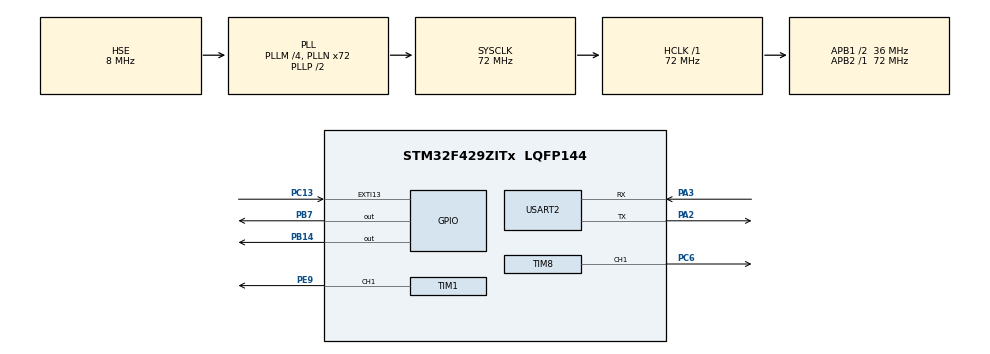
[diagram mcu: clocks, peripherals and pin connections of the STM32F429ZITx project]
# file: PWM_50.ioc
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Mcu.Family=STM32F4
Mcu.Name=STM32F429ZITx
Mcu.Package=LQFP144
NVIC.PriorityGroup=NVIC_PRIORITYGROUP_4
PA13.Mode=Serial_Wire
PA13.Signal=SYS_JTMS-SWDIO
PA14.Mode=Serial_Wire
PA14.Signal=SYS_JTCK-SWCLK
PA2.Mode=Asynchronous
PA2.Signal=USART2_TX
PA3.Mode=Asynchronous
PA3.Signal=USART2_RX
PB14.Signal=GPIO_Output
PB7.Signal=GPIO_Output
PC13.Signal=GPXTI13
PC6.Signal=S_TIM8_CH1
PE9.Signal=S_TIM1_CH1
PH0/OSC_IN.Mode=HSE-External-Oscillator
PH0/OSC_IN.Signal=RCC_OSC_IN
PH1/OSC_OUT.Mode=HSE-External-Oscillator
PH1/OSC_OUT.Signal=RCC_OSC_OUT
ProjectManager.HeapSize=0x200
ProjectManager.StackSize=0x400
ProjectManager.TargetToolchain=STM32CubeIDE
RCC.48MHZClocksFreq_Value=36000000
RCC.AHBFreq_Value=72000000
RCC.APB1CLKDivider=RCC_HCLK_DIV2
RCC.APB1Freq_Value=36000000
RCC.APB1TimFreq_Value=72000000
RCC.APB2Freq_Value=72000000
RCC.APB2TimFreq_Value=72000000
RCC.CortexFreq_Value=72000000
RCC.HCLKFreq_Value=72000000
RCC.HSE_VALUE=8000000
RCC.HSI_VALUE=16000000
RCC.LSE_VALUE=32768
RCC.PLLM=4
RCC.PLLN=72
RCC.PLLSourceVirtual=RCC_PLLSOURCE_HSE
RCC.SYSCLKFreq_VALUE=72000000
RCC.SYSCLKSource=RCC_SYSCLKSOURCE_PLLCLK
RCC.VCOOutputFreq_Value=144000000
SH.S_TIM1_CH1.0=TIM1_CH1,PWM Generation1 CH1
SH.S_TIM8_CH1.0=TIM8_CH1,PWM Generation1 CH1
TIM1.Channel-Output\ Compare2\ No\ Output=TIM_CHANNEL_2
TIM1.Channel-PWM\ Generation1\ CH1=TIM_CHANNEL_1
TIM1.OCMode_2=TIM_OCMODE_ACTIVE
TIM1.Period=199
TIM1.Prescaler=71
TIM1.Pulse-Output\ Compare2\ No\ Output=100
TIM1.Pulse-PWM\ Generation1\ CH1=100
TIM1.TIM_MasterOutputTrigger=TIM_TRGO_OC2REF
TIM8.Channel-PWM\ Generation1\ CH1=TIM_CHANNEL_1
TIM8.Period=199
TIM8.Prescaler=71
TIM8.Pulse-PWM\ Generation1\ CH1=100
TIM8.TIM_MasterOutputTrigger=TIM_TRGO_RESET
USART2.VirtualMode=VM_ASYNC
VP_TIM1_VS_ClockSourceINT.Mode=Internal
VP_TIM1_VS_no_output2.Mode=Output Compare2 No Output
VP_TIM8_VS_ClockSourceITR.Mode=TriggerSource_ITR0
VP_TIM8_VS_ControllerModeTrigger.Mode=Trigger Mode
board=custom

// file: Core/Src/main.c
/* USER CODE BEGIN Header */
/**
  ******************************************************************************
  * @file           : main.c
  * @brief          : Main program body
  ******************************************************************************
  * @attention
  *
  * Copyright (c) 2023 STMicroelectronics.
  * All rights reserved.
  *
  * This software is licensed under terms that can be found in the LICENSE file
  * in the root directory of this software component.
  * If no LICENSE file comes with this software, it is provided AS-IS.
  *
  ******************************************************************************
  */
/* USER CODE END Header */
#include "main.h"

/* USER CODE BEGIN Includes */
#include<stdio.h>
/* USER CODE END Includes */

TIM_HandleTypeDef htim1;
TIM_HandleTypeDef htim8;

UART_HandleTypeDef huart2;

void SystemClock_Config(void);
static void MX_GPIO_Init(void);
static void MX_TIM1_Init(void);
static void MX_USART2_UART_Init(void);
static void MX_TIM8_Init(void);

/* USER CODE BEGIN 0 */
int _write(int file, char *ptr, int len)
{
	HAL_UART_Transmit(&huart2, (uint8_t *)ptr, len, HAL_MAX_DELAY);
	return len;
}
/* USER CODE END 0 */

int main(void)
{

  /* MCU Configuration--------------------------------------------------------*/

  /* Reset of all peripherals, Initializes the Flash interface and the Systick. */
  HAL_Init();

  /* Configure the system clock */
  SystemClock_Config();

  /* Initialize all configured peripherals */
  MX_GPIO_Init();
  MX_TIM1_Init();
  MX_USART2_UART_Init();
  MX_TIM8_Init();
  /* USER CODE BEGIN 2 */

  HAL_TIM_PWM_Start(&htim1, TIM_CHANNEL_1);
  HAL_TIM_OC_Start(&htim1, TIM_CHANNEL_2);

  HAL_TIM_PWM_Start(&htim8, TIM_CHANNEL_1);

  /* USER CODE END 2 */

  /* Infinite loop */
  while (1)
  {

  }
}

void SystemClock_Config(void)
{
  RCC_OscInitTypeDef RCC_OscInitStruct = {0};
  RCC_ClkInitTypeDef RCC_ClkInitStruct = {0};

  /** Configure the main internal regulator output voltage
  */
  __HAL_RCC_PWR_CLK_ENABLE();
  __HAL_PWR_VOLTAGESCALING_CONFIG(PWR_REGULATOR_VOLTAGE_SCALE3);

  /** Initializes the RCC Oscillators according to the specified parameters
  * in the RCC_OscInitTypeDef structure.
  */
  RCC_OscInitStruct.OscillatorType = RCC_OSCILLATORTYPE_HSE;
  RCC_OscInitStruct.HSEState = RCC_HSE_ON;
  RCC_OscInitStruct.PLL.PLLState = RCC_PLL_ON;
  RCC_OscInitStruct.PLL.PLLSource = RCC_PLLSOURCE_HSE;
  RCC_OscInitStruct.PLL.PLLM = 4;
  RCC_OscInitStruct.PLL.PLLN = 72;
  RCC_OscInitStruct.PLL.PLLP = RCC_PLLP_DIV2;
  RCC_OscInitStruct.PLL.PLLQ = 4;
  if (HAL_RCC_OscConfig(&RCC_OscInitStruct) != HAL_OK)
  {
    Error_Handler();
  }

  /** Initializes the CPU, AHB and APB buses clocks
  */
  RCC_ClkInitStruct.ClockType = RCC_CLOCKTYPE_HCLK|RCC_CLOCKTYPE_SYSCLK
                              |RCC_CLOCKTYPE_PCLK1|RCC_CLOCKTYPE_PCLK2;
  RCC_ClkInitStruct.SYSCLKSource = RCC_SYSCLKSOURCE_PLLCLK;
  RCC_ClkInitStruct.AHBCLKDivider = RCC_SYSCLK_DIV1;
  RCC_ClkInitStruct.APB1CLKDivider = RCC_HCLK_DIV2;
  RCC_ClkInitStruct.APB2CLKDivider = RCC_HCLK_DIV1;

  if (HAL_RCC_ClockConfig(&RCC_ClkInitStruct, FLASH_LATENCY_2) != HAL_OK)
  {
    Error_Handler();
  }
}

static void MX_TIM1_Init(void)
{

  TIM_ClockConfigTypeDef sClockSourceConfig = {0};
  TIM_MasterConfigTypeDef sMasterConfig = {0};
  TIM_OC_InitTypeDef sConfigOC = {0};
  TIM_BreakDeadTimeConfigTypeDef sBreakDeadTimeConfig = {0};

  htim1.Instance = TIM1;
  htim1.Init.Prescaler = 71;
  htim1.Init.CounterMode = TIM_COUNTERMODE_UP;
  htim1.Init.Period = 199;
  htim1.Init.ClockDivision = TIM_CLOCKDIVISION_DIV1;
  htim1.Init.RepetitionCounter = 0;
  htim1.Init.AutoReloadPreload = TIM_AUTORELOAD_PRELOAD_DISABLE;
  if (HAL_TIM_Base_Init(&htim1) != HAL_OK)
  {
    Error_Handler();
  }
  sClockSourceConfig.ClockSource = TIM_CLOCKSOURCE_INTERNAL;
  if (HAL_TIM_ConfigClockSource(&htim1, &sClockSourceConfig) != HAL_OK)
  {
    Error_Handler();
  }
  if (HAL_TIM_PWM_Init(&htim1) != HAL_OK)
  {
    Error_Handler();
  }
  if (HAL_TIM_OC_Init(&htim1) != HAL_OK)
  {
    Error_Handler();
  }
  sMasterConfig.MasterOutputTrigger = TIM_TRGO_OC2REF;
  sMasterConfig.MasterSlaveMode = TIM_MASTERSLAVEMODE_DISABLE;
  if (HAL_TIMEx_MasterConfigSynchronization(&htim1, &sMasterConfig) != HAL_OK)
  {
    Error_Handler();
  }
  sConfigOC.OCMode = TIM_OCMODE_PWM1;
  sConfigOC.Pulse = 100;
  sConfigOC.OCPolarity = TIM_OCPOLARITY_HIGH;
  sConfigOC.OCNPolarity = TIM_OCNPOLARITY_HIGH;
  sConfigOC.OCFastMode = TIM_OCFAST_DISABLE;
  sConfigOC.OCIdleState = TIM_OCIDLESTATE_RESET;
  sConfigOC.OCNIdleState = TIM_OCNIDLESTATE_RESET;
  if (HAL_TIM_PWM_ConfigChannel(&htim1, &sConfigOC, TIM_CHANNEL_1) != HAL_OK)
  {
    Error_Handler();
  }
  sConfigOC.OCMode = TIM_OCMODE_ACTIVE;
  if (HAL_TIM_OC_ConfigChannel(&htim1, &sConfigOC, TIM_CHANNEL_2) != HAL_OK)
  {
    Error_Handler();
  }
  sBreakDeadTimeConfig.OffStateRunMode = TIM_OSSR_DISABLE;
  sBreakDeadTimeConfig.OffStateIDLEMode = TIM_OSSI_DISABLE;
  sBreakDeadTimeConfig.LockLevel = TIM_LOCKLEVEL_OFF;
  sBreakDeadTimeConfig.DeadTime = 0;
  sBreakDeadTimeConfig.BreakState = TIM_BREAK_DISABLE;
  sBreakDeadTimeConfig.BreakPolarity = TIM_BREAKPOLARITY_HIGH;
  sBreakDeadTimeConfig.AutomaticOutput = TIM_AUTOMATICOUTPUT_DISABLE;
  if (HAL_TIMEx_ConfigBreakDeadTime(&htim1, &sBreakDeadTimeConfig) != HAL_OK)
  {
    Error_Handler();
  }
  HAL_TIM_MspPostInit(&htim1);

}

static void MX_TIM8_Init(void)
{

  TIM_SlaveConfigTypeDef sSlaveConfig = {0};
  TIM_MasterConfigTypeDef sMasterConfig = {0};
  TIM_OC_InitTypeDef sConfigOC = {0};
  TIM_BreakDeadTimeConfigTypeDef sBreakDeadTimeConfig = {0};

  htim8.Instance = TIM8;
  htim8.Init.Prescaler = 71;
  htim8.Init.CounterMode = TIM_COUNTERMODE_UP;
  htim8.Init.Period = 199;
  htim8.Init.ClockDivision = TIM_CLOCKDIVISION_DIV1;
  htim8.Init.RepetitionCounter = 0;
  htim8.Init.AutoReloadPreload = TIM_AUTORELOAD_PRELOAD_DISABLE;
  if (HAL_TIM_Base_Init(&htim8) != HAL_OK)
  {
    Error_Handler();
  }
  if (HAL_TIM_PWM_Init(&htim8) != HAL_OK)
  {
    Error_Handler();
  }
  sSlaveConfig.SlaveMode = TIM_SLAVEMODE_TRIGGER;
  sSlaveConfig.InputTrigger = TIM_TS_ITR0;
  if (HAL_TIM_SlaveConfigSynchro(&htim8, &sSlaveConfig) != HAL_OK)
  {
    Error_Handler();
  }
  sMasterConfig.MasterOutputTrigger = TIM_TRGO_RESET;
  sMasterConfig.MasterSlaveMode = TIM_MASTERSLAVEMODE_DISABLE;
  if (HAL_TIMEx_MasterConfigSynchronization(&htim8, &sMasterConfig) != HAL_OK)
  {
    Error_Handler();
  }
  sConfigOC.OCMode = TIM_OCMODE_PWM1;
  sConfigOC.Pulse = 100;
  sConfigOC.OCPolarity = TIM_OCPOLARITY_HIGH;
  sConfigOC.OCNPolarity = TIM_OCNPOLARITY_HIGH;
  sConfigOC.OCFastMode = TIM_OCFAST_DISABLE;
  sConfigOC.OCIdleState = TIM_OCIDLESTATE_RESET;
  sConfigOC.OCNIdleState = TIM_OCNIDLESTATE_RESET;
  if (HAL_TIM_PWM_ConfigChannel(&htim8, &sConfigOC, TIM_CHANNEL_1) != HAL_OK)
  {
    Error_Handler();
  }
  sBreakDeadTimeConfig.OffStateRunMode = TIM_OSSR_DISABLE;
  sBreakDeadTimeConfig.OffStateIDLEMode = TIM_OSSI_DISABLE;
  sBreakDeadTimeConfig.LockLevel = TIM_LOCKLEVEL_OFF;
  sBreakDeadTimeConfig.DeadTime = 0;
  sBreakDeadTimeConfig.BreakState = TIM_BREAK_DISABLE;
  sBreakDeadTimeConfig.BreakPolarity = TIM_BREAKPOLARITY_HIGH;
  sBreakDeadTimeConfig.AutomaticOutput = TIM_AUTOMATICOUTPUT_DISABLE;
  if (HAL_TIMEx_ConfigBreakDeadTime(&htim8, &sBreakDeadTimeConfig) != HAL_OK)
  {
    Error_Handler();
  }
  HAL_TIM_MspPostInit(&htim8);

}

static void MX_USART2_UART_Init(void)
{

  huart2.Instance = USART2;
  huart2.Init.BaudRate = 115200;
  huart2.Init.WordLength = UART_WORDLENGTH_8B;
  huart2.Init.StopBits = UART_STOPBITS_1;
  huart2.Init.Parity = UART_PARITY_NONE;
  huart2.Init.Mode = UART_MODE_TX_RX;
  huart2.Init.HwFlowCtl = UART_HWCONTROL_NONE;
  huart2.Init.OverSampling = UART_OVERSAMPLING_16;
  if (HAL_UART_Init(&huart2) != HAL_OK)
  {
    Error_Handler();
  }

}

static void MX_GPIO_Init(void)
{
  GPIO_InitTypeDef GPIO_InitStruct = {0};

  /* GPIO Ports Clock Enable */
  __HAL_RCC_GPIOC_CLK_ENABLE();
  __HAL_RCC_GPIOH_CLK_ENABLE();
  __HAL_RCC_GPIOA_CLK_ENABLE();
  __HAL_RCC_GPIOE_CLK_ENABLE();
  __HAL_RCC_GPIOB_CLK_ENABLE();

  /*Configure GPIO pin Output Level */
  HAL_GPIO_WritePin(GPIOB, GPIO_PIN_14|GPIO_PIN_7, GPIO_PIN_RESET);

  /*Configure GPIO pin : PC13 */
  GPIO_InitStruct.Pin = GPIO_PIN_13;
  GPIO_InitStruct.Mode = GPIO_MODE_IT_RISING;
  GPIO_InitStruct.Pull = GPIO_NOPULL;
  HAL_GPIO_Init(GPIOC, &GPIO_InitStruct);

  /*Configure GPIO pins : PB14 PB7 */
  GPIO_InitStruct.Pin = GPIO_PIN_14|GPIO_PIN_7;
  GPIO_InitStruct.Mode = GPIO_MODE_OUTPUT_PP;
  GPIO_InitStruct.Pull = GPIO_NOPULL;
  GPIO_InitStruct.Speed = GPIO_SPEED_FREQ_LOW;
  HAL_GPIO_Init(GPIOB, &GPIO_InitStruct);

}

void Error_Handler(void)
{
  __disable_irq();
  while (1)
  {
  }
}
